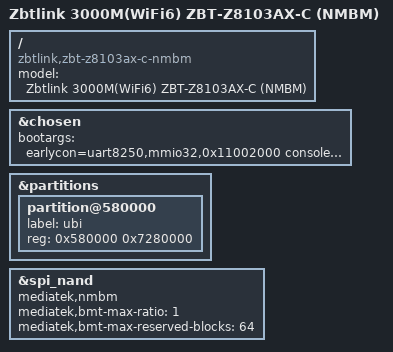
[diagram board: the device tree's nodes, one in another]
// SPDX-License-Identifier: GPL-2.0-or-later OR MIT

/dts-v1/;

#include "mt7981b-zbtlink-zbt-z8103ax.dtsi"

/ {
	model = "Zbtlink 3000M(WiFi6) ZBT-Z8103AX-C (NMBM)";
	compatible = "zbtlink,zbt-z8103ax-c-nmbm", "mediatek,mt7981b";
};

&chosen {
	bootargs = "earlycon=uart8250,mmio32,0x11002000 console=ttyS0,115200n8 loglevel=8";
};

&partitions {
	partition@580000 {
		label = "ubi";
		reg = <0x580000 0x7280000>;
	};
};

&spi_nand {
	mediatek,nmbm;
	mediatek,bmt-max-ratio = <1>;
	mediatek,bmt-max-reserved-blocks = <64>;
};
